# STM32F30xxx register map
File version: 1.0
Registers are 32-bit, read-write, reset 0x0 unless marked. A register's access mark holds for its fields unless they carry their own. Offsets are from the block's base; [hi:lo] are bit positions; lines under a group give offsets from that group; {n}, {i} and the like mark numbered series.

## TSC — Touch sensing controller
Base 0x40024000
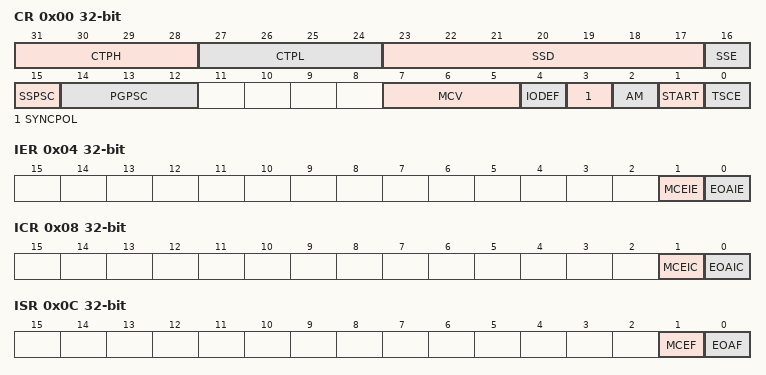
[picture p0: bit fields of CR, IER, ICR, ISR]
0x00 CR — control register
  [31:28] CTPH — Charge transfer pulse high
  [27:24] CTPL — Charge transfer pulse low
  [23:17] SSD — Spread spectrum deviation
  [16] SSE — Spread spectrum enable
  [15] SSPSC — Spread spectrum prescaler
  [14:12] PGPSC — pulse generator prescaler
  [7:5] MCV — Max count value
  [4] IODEF — I/O Default mode
  [3] SYNCPOL — Synchronization pin polarity
  [2] AM — Acquisition mode
  [1] START — Start a new acquisition
  [0] TSCE — Touch sensing controller enable
0x04 IER — interrupt enable register
  [1] MCEIE — Max count error interrupt enable
  [0] EOAIE — End of acquisition interrupt enable
0x08 ICR — interrupt clear register
  [1] MCEIC — Max count error interrupt clear
  [0] EOAIC — End of acquisition interrupt clear
0x0C ISR — interrupt status register
  [1] MCEF — Max count error flag
  [0] EOAF — End of acquisition flag
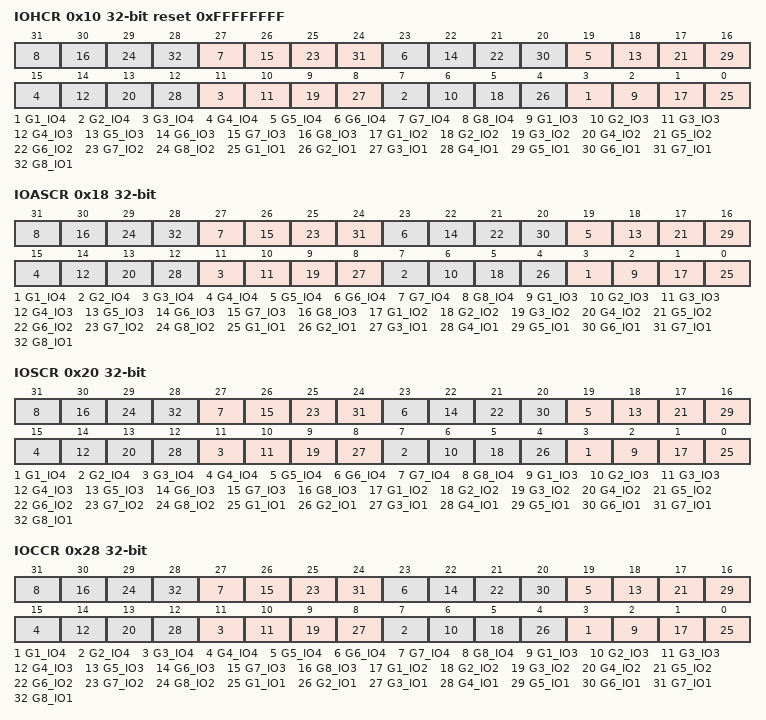
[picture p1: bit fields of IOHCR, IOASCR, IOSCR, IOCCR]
0x10 IOHCR reset 0xFFFFFFFF — I/O hysteresis control register
  [4n-1] G{n}_IO4 (n=1..8) — G{n}_IO4 Schmitt trigger hysteresis mode
  [4n-2] G{n}_IO3 (n=1..8) — G{n}_IO3 Schmitt trigger hysteresis mode
  [4n-3] G{n}_IO2 (n=1..8) — G{n}_IO2 Schmitt trigger hysteresis mode
  [4n-4] G{n}_IO1 (n=1..8) — G{n}_IO1 Schmitt trigger hysteresis mode
0x18 IOASCR — I/O analog switch control register
  [4n-1] G{n}_IO4 (n=1..8) — G{n}_IO4 analog switch enable
  [4n-2] G{n}_IO3 (n=1..8) — G{n}_IO3 analog switch enable
  [4n-3] G{n}_IO2 (n=1..8) — G{n}_IO2 analog switch enable
  [4n-4] G{n}_IO1 (n=1..8) — G{n}_IO1 analog switch enable
0x20 IOSCR — I/O sampling control register
  [4n-1] G{n}_IO4 (n=1..8) — G{n}_IO4 sampling mode
  [4n-2] G{n}_IO3 (n=1..8) — G{n}_IO3 sampling mode
  [4n-3] G{n}_IO2 (n=1..8) — G{n}_IO2 sampling mode
  [4n-4] G{n}_IO1 (n=1..8) — G{n}_IO1 sampling mode
0x28 IOCCR — I/O channel control register
  [4n-1] G{n}_IO4 (n=1..8) — G{n}_IO4 channel mode
  [4n-2] G{n}_IO3 (n=1..8) — G{n}_IO3 channel mode
  [4n-3] G{n}_IO2 (n=1..8) — G{n}_IO2 channel mode
  [4n-4] G{n}_IO1 (n=1..8) — G{n}_IO1 channel mode
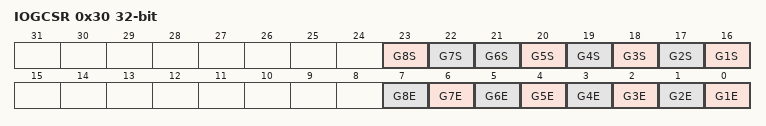
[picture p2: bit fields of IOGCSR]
0x30 IOGCSR access per field — I/O group control status register
  [23] G8S rw — Analog I/O group x status
  [22] G7S rw — Analog I/O group x status
  [n+15] G{n}S ro (n=1..6) — Analog I/O group x status
  [n-1] G{n}E rw (n=1..8) — Analog I/O group x enable
{0x30+4i} IOG{i}CR ro (i=1..8) — I/O group x counter register
  [13:0] CNT — Counter value

## CRC — cyclic redundancy check calculation unit
Base 0x40023000
0x00 DR reset 0xFFFFFFFF — Data register
  [31:0] DR — Data register bits
0x04 IDR — Independent data register
  [7:0] IDR — General-purpose 8-bit data register bits
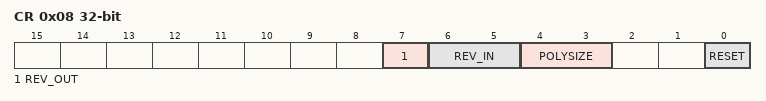
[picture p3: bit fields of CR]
0x08 CR — Control register
  [7] REV_OUT — Reverse output data
  [6:5] REV_IN — Reverse input data
  [4:3] POLYSIZE — Polynomial size
  [0] RESET — reset bit
0x10 INIT reset 0xFFFFFFFF — Initial CRC value
  [31:0] INIT — Programmable initial CRC value
0x14 POL reset 0x4C11DB7 — CRC polynomial
  [31:0] POL — Programmable polynomial

## Flash
Base 0x40022000
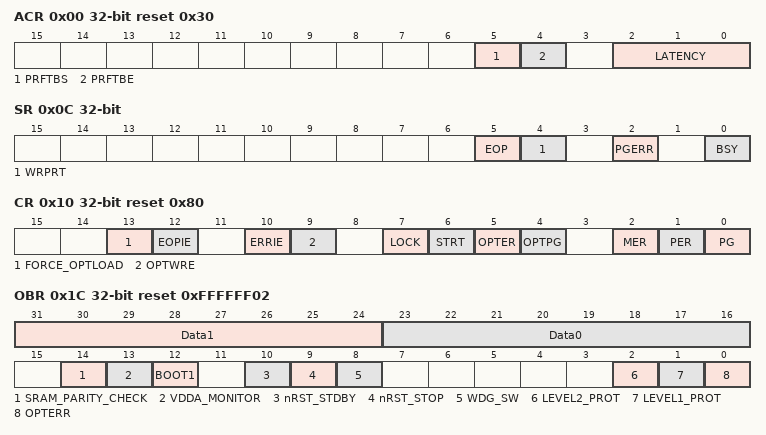
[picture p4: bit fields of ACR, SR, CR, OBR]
0x00 ACR access per field reset 0x30 — Flash access control register
  [5] PRFTBS ro, [4] PRFTBE rw, [2:0] LATENCY rw
0x04 KEYR wo — Flash key register
  [31:0] FKEYR — Flash Key
0x08 OPTKEYR wo — Flash option key register
  [31:0] OPTKEYR — Option byte key
0x0C SR access per field — Flash status register
  [5] EOP rw — End of operation
  [4] WRPRT rw — Write protection error
  [2] PGERR rw — Programming error
  [0] BSY ro — Busy
0x10 CR reset 0x80 — Flash control register
  [13] FORCE_OPTLOAD — Force option byte loading
  [12] EOPIE — End of operation interrupt enable
  [10] ERRIE — Error interrupt enable
  [9] OPTWRE — Option bytes write enable
  [7] LOCK
  [6] STRT — Start
  [5] OPTER — Option byte erase
  [4] OPTPG — Option byte programming
  [2] MER — Mass erase
  [1] PER — Page erase
  [0] PG — Programming
0x14 AR wo — Flash address register
  [31:0] FAR — Flash address
0x1C OBR ro reset 0xFFFFFF02 — Option byte register
  [31:24] Data1
  [23:16] Data0
  [14] SRAM_PARITY_CHECK
  [13] VDDA_MONITOR
  [12] BOOT1
  [10] nRST_STDBY
  [9] nRST_STOP
  [8] WDG_SW
  [2] LEVEL2_PROT — Level 2 protection status
  [1] LEVEL1_PROT — Level 1 protection status
  [0] OPTERR — Option byte error
0x20 WRPR ro reset 0xFFFFFFFF — Write protection register
  [31:0] WRP — Write protect
